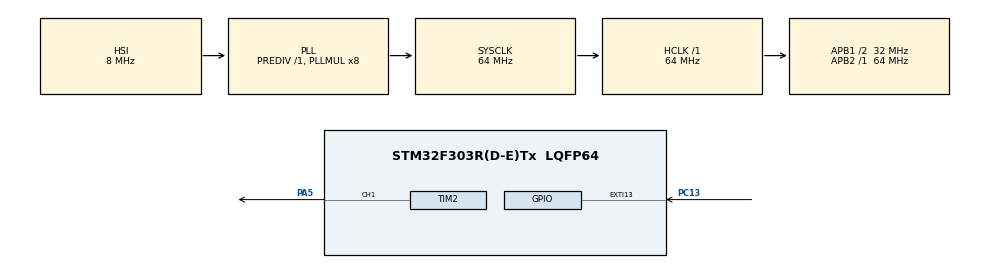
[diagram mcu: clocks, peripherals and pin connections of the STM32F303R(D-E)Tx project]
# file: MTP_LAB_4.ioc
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Mcu.Family=STM32F3
Mcu.Name=STM32F303R(D-E)Tx
Mcu.Package=LQFP64
NVIC.EXTI15_10_IRQn=true\:8\:0\:true\:false\:true\:true\:false
NVIC.PriorityGroup=NVIC_PRIORITYGROUP_4
NVIC.TIM6_DAC_IRQn=true\:8\:0\:true\:false\:true\:true\:true
PA13.Mode=Serial_Wire
PA13.Signal=SYS_JTMS-SWDIO
PA14.Mode=Serial_Wire
PA14.Signal=SYS_JTCK-SWCLK
PA5.Signal=S_TIM2_CH1_ETR
PC13.GPIO_ModeDefaultEXTI=GPIO_MODE_IT_FALLING
PC13.GPIO_PuPd=GPIO_PULLUP
PC13.Signal=GPXTI13
ProjectManager.HeapSize=0x200
ProjectManager.StackSize=0x400
ProjectManager.TargetToolchain=STM32CubeIDE
RCC.AHBFreq_Value=64000000
RCC.APB1CLKDivider=RCC_HCLK_DIV2
RCC.APB1Freq_Value=32000000
RCC.APB1TimFreq_Value=64000000
RCC.APB2Freq_Value=64000000
RCC.APB2TimFreq_Value=64000000
RCC.CortexFreq_Value=64000000
RCC.HCLKFreq_Value=64000000
RCC.HSE_VALUE=8000000
RCC.HSI_VALUE=8000000
RCC.LSE_VALUE=32768
RCC.PLLMUL=RCC_PLL_MUL8
RCC.SYSCLKFreq_VALUE=64000000
RCC.SYSCLKSourceVirtual=RCC_SYSCLKSOURCE_PLLCLK
RCC.USBFreq_Value=64000000
SH.S_TIM2_CH1_ETR.0=TIM2_CH1,PWM Generation1 CH1
TIM2.Channel-PWM\ Generation1\ CH1=TIM_CHANNEL_1
TIM2.Period=999999
TIM2.Prescaler=63
TIM2.Pulse-PWM\ Generation1\ CH1=499999
TIM6.AutoReloadPreload=TIM_AUTORELOAD_PRELOAD_DISABLE
TIM6.Period=999
TIM6.Prescaler=36999
VP_TIM2_VS_ClockSourceINT.Mode=Internal
VP_TIM6_VS_ClockSourceINT.Mode=Enable_Timer
VP_TIM6_VS_OPM.Mode=OPM_bit
board=custom

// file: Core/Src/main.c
/* USER CODE BEGIN Header */
/**
  ******************************************************************************
  * @file           : main.c
  * @brief          : Main program body
  ******************************************************************************
  * @attention
  *
  * <h2><center>&copy; Copyright (c) 2021 STMicroelectronics.
  * All rights reserved.</center></h2>
  *
  * This software component is licensed by ST under BSD 3-Clause license,
  * the "License"; You may not use this file except in compliance with the
  * License. You may obtain a copy of the License at:
  *                        opensource.org/licenses/BSD-3-Clause
  *
  ******************************************************************************
  */
/* USER CODE END Header */

#include "main.h"

TIM_HandleTypeDef htim2;
TIM_HandleTypeDef htim6;

void SystemClock_Config(void);
static void MX_GPIO_Init(void);
static void MX_TIM6_Init(void);
static void MX_TIM2_Init(void);

int main(void)
{

  /* MCU Configuration--------------------------------------------------------*/

  /* Reset of all peripherals, Initializes the Flash interface and the Systick. */
  HAL_Init();

  /* Configure the system clock */
  SystemClock_Config();

  /* Initialize all configured peripherals */
  MX_GPIO_Init();
  MX_TIM6_Init();
  MX_TIM2_Init();
  /* USER CODE BEGIN 2 */
  __HAL_TIM_CLEAR_IT(&htim6, TIM_IT_UPDATE);
  __HAL_TIM_ENABLE_IT(&htim6, TIM_IT_UPDATE);
  HAL_TIM_PWM_Start(&htim2, TIM_CHANNEL_1);
  /* USER CODE END 2 */

  /* Infinite loop */
  while (1)
  {

  }
}

void SystemClock_Config(void)
{
  RCC_OscInitTypeDef RCC_OscInitStruct = {0};
  RCC_ClkInitTypeDef RCC_ClkInitStruct = {0};
  RCC_PeriphCLKInitTypeDef PeriphClkInit = {0};

  /** Initializes the CPU, AHB and APB busses clocks
  */
  RCC_OscInitStruct.OscillatorType = RCC_OSCILLATORTYPE_HSI;
  RCC_OscInitStruct.HSIState = RCC_HSI_ON;
  RCC_OscInitStruct.HSICalibrationValue = RCC_HSICALIBRATION_DEFAULT;
  RCC_OscInitStruct.PLL.PLLState = RCC_PLL_ON;
  RCC_OscInitStruct.PLL.PLLSource = RCC_PLLSOURCE_HSI;
  RCC_OscInitStruct.PLL.PLLMUL = RCC_PLL_MUL8;
  RCC_OscInitStruct.PLL.PREDIV = RCC_PREDIV_DIV1;
  if (HAL_RCC_OscConfig(&RCC_OscInitStruct) != HAL_OK)
  {
    Error_Handler();
  }
  /** Initializes the CPU, AHB and APB busses clocks
  */
  RCC_ClkInitStruct.ClockType = RCC_CLOCKTYPE_HCLK|RCC_CLOCKTYPE_SYSCLK
                              |RCC_CLOCKTYPE_PCLK1|RCC_CLOCKTYPE_PCLK2;
  RCC_ClkInitStruct.SYSCLKSource = RCC_SYSCLKSOURCE_PLLCLK;
  RCC_ClkInitStruct.AHBCLKDivider = RCC_SYSCLK_DIV1;
  RCC_ClkInitStruct.APB1CLKDivider = RCC_HCLK_DIV2;
  RCC_ClkInitStruct.APB2CLKDivider = RCC_HCLK_DIV1;

  if (HAL_RCC_ClockConfig(&RCC_ClkInitStruct, FLASH_LATENCY_2) != HAL_OK)
  {
    Error_Handler();
  }
  PeriphClkInit.PeriphClockSelection = RCC_PERIPHCLK_TIM2;
  PeriphClkInit.Tim2ClockSelection = RCC_TIM2CLK_HCLK;
  if (HAL_RCCEx_PeriphCLKConfig(&PeriphClkInit) != HAL_OK)
  {
    Error_Handler();
  }
}

static void MX_TIM2_Init(void)
{

  TIM_ClockConfigTypeDef sClockSourceConfig = {0};
  TIM_MasterConfigTypeDef sMasterConfig = {0};
  TIM_OC_InitTypeDef sConfigOC = {0};

  htim2.Instance = TIM2;
  htim2.Init.Prescaler = 63;
  htim2.Init.CounterMode = TIM_COUNTERMODE_UP;
  htim2.Init.Period = 999999;
  htim2.Init.ClockDivision = TIM_CLOCKDIVISION_DIV1;
  htim2.Init.AutoReloadPreload = TIM_AUTORELOAD_PRELOAD_DISABLE;
  if (HAL_TIM_Base_Init(&htim2) != HAL_OK)
  {
    Error_Handler();
  }
  sClockSourceConfig.ClockSource = TIM_CLOCKSOURCE_INTERNAL;
  if (HAL_TIM_ConfigClockSource(&htim2, &sClockSourceConfig) != HAL_OK)
  {
    Error_Handler();
  }
  if (HAL_TIM_PWM_Init(&htim2) != HAL_OK)
  {
    Error_Handler();
  }
  sMasterConfig.MasterOutputTrigger = TIM_TRGO_RESET;
  sMasterConfig.MasterSlaveMode = TIM_MASTERSLAVEMODE_DISABLE;
  if (HAL_TIMEx_MasterConfigSynchronization(&htim2, &sMasterConfig) != HAL_OK)
  {
    Error_Handler();
  }
  sConfigOC.OCMode = TIM_OCMODE_PWM1;
  sConfigOC.Pulse = 499999;
  sConfigOC.OCPolarity = TIM_OCPOLARITY_HIGH;
  sConfigOC.OCFastMode = TIM_OCFAST_DISABLE;
  if (HAL_TIM_PWM_ConfigChannel(&htim2, &sConfigOC, TIM_CHANNEL_1) != HAL_OK)
  {
    Error_Handler();
  }
  HAL_TIM_MspPostInit(&htim2);

}

static void MX_TIM6_Init(void)
{

  TIM_MasterConfigTypeDef sMasterConfig = {0};

  htim6.Instance = TIM6;
  htim6.Init.Prescaler = 36999;
  htim6.Init.CounterMode = TIM_COUNTERMODE_UP;
  htim6.Init.Period = 999;
  htim6.Init.AutoReloadPreload = TIM_AUTORELOAD_PRELOAD_DISABLE;
  if (HAL_TIM_Base_Init(&htim6) != HAL_OK)
  {
    Error_Handler();
  }
  if (HAL_TIM_OnePulse_Init(&htim6, TIM_OPMODE_SINGLE) != HAL_OK)
  {
    Error_Handler();
  }
  sMasterConfig.MasterOutputTrigger = TIM_TRGO_RESET;
  sMasterConfig.MasterSlaveMode = TIM_MASTERSLAVEMODE_DISABLE;
  if (HAL_TIMEx_MasterConfigSynchronization(&htim6, &sMasterConfig) != HAL_OK)
  {
    Error_Handler();
  }

}

static void MX_GPIO_Init(void)
{
  GPIO_InitTypeDef GPIO_InitStruct = {0};

  /* GPIO Ports Clock Enable */
  __HAL_RCC_GPIOC_CLK_ENABLE();
  __HAL_RCC_GPIOA_CLK_ENABLE();

  /*Configure GPIO pin : PC13 */
  GPIO_InitStruct.Pin = GPIO_PIN_13;
  GPIO_InitStruct.Mode = GPIO_MODE_IT_FALLING;
  GPIO_InitStruct.Pull = GPIO_PULLUP;
  HAL_GPIO_Init(GPIOC, &GPIO_InitStruct);

  /* EXTI interrupt init*/
  HAL_NVIC_SetPriority(EXTI15_10_IRQn, 8, 0);
  HAL_NVIC_EnableIRQ(EXTI15_10_IRQn);

}

void Error_Handler(void)
{
}

/************************ (C) COPYRIGHT STMicroelectronics *****END OF FILE****/
